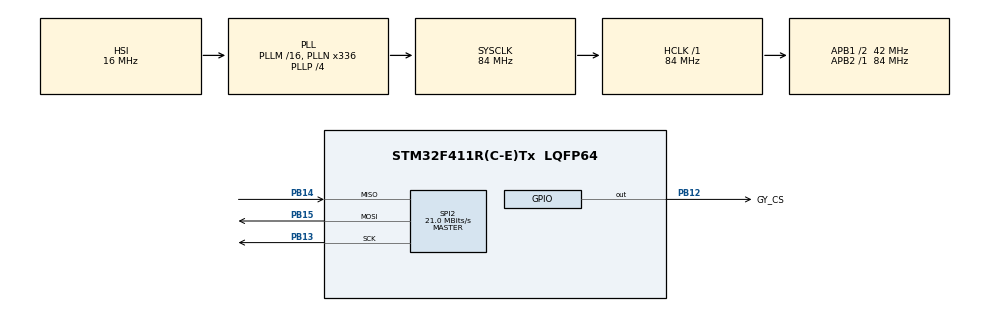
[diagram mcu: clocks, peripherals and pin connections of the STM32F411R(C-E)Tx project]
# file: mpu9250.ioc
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Mcu.Family=STM32F4
Mcu.Name=STM32F411R(C-E)Tx
Mcu.Package=LQFP64
NVIC.PriorityGroup=NVIC_PRIORITYGROUP_0
PA13.Mode=Serial_Wire
PA13.Signal=SYS_JTMS-SWDIO
PA14.Mode=Serial_Wire
PA14.Signal=SYS_JTCK-SWCLK
PB12.GPIO_Label=GY_CS
PB12.Signal=GPIO_Output
PB13.Mode=Full_Duplex_Master
PB13.Signal=SPI2_SCK
PB14.Mode=Full_Duplex_Master
PB14.Signal=SPI2_MISO
PB15.Mode=Full_Duplex_Master
PB15.Signal=SPI2_MOSI
PH0\ -\ OSC_IN.Mode=HSE-External-Oscillator
PH0\ -\ OSC_IN.Signal=RCC_OSC_IN
PH1\ -\ OSC_OUT.Mode=HSE-External-Oscillator
PH1\ -\ OSC_OUT.Signal=RCC_OSC_OUT
ProjectManager.HeapSize=0x200
ProjectManager.StackSize=0x400
ProjectManager.TargetToolchain=MDK-ARM V5
RCC.48MHZClocksFreq_Value=84000000
RCC.AHBFreq_Value=84000000
RCC.APB1CLKDivider=RCC_HCLK_DIV2
RCC.APB1Freq_Value=42000000
RCC.APB1TimFreq_Value=84000000
RCC.APB2Freq_Value=84000000
RCC.APB2TimFreq_Value=84000000
RCC.CortexFreq_Value=84000000
RCC.FLatency-AdvancedSettings=FLASH_LATENCY_2
RCC.HCLKFreq_Value=84000000
RCC.HSE_VALUE=8000000
RCC.HSI_VALUE=16000000
RCC.LSE_VALUE=32768
RCC.PLLN=336
RCC.PLLP=RCC_PLLP_DIV4
RCC.SYSCLKFreq_VALUE=84000000
RCC.SYSCLKSource=RCC_SYSCLKSOURCE_PLLCLK
RCC.VCOOutputFreq_Value=336000000
SPI2.CalculateBaudRate=21.0 MBits/s
SPI2.Direction=SPI_DIRECTION_2LINES
SPI2.Mode=SPI_MODE_MASTER
SPI2.VirtualType=VM_MASTER
board=NUCLEO-F411RE

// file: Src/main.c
/* USER CODE BEGIN Header */
/**
  ******************************************************************************
  * @file           : main.c
  * @brief          : Main program body
  ******************************************************************************
  ** This notice applies to any and all portions of this file
  * that are not between comment pairs USER CODE BEGIN and
  * USER CODE END. Other portions of this file, whether
  * inserted by the user or by software development tools
  * are owned by their respective copyright owners.
  *
  * COPYRIGHT(c) 2019 STMicroelectronics
  *
  * Redistribution and use in source and binary forms, with or without modification,
  * are permitted provided that the following conditions are met:
  *   1. Redistributions of source code must retain the above copyright notice,
  *      this list of conditions and the following disclaimer.
  *   2. Redistributions in binary form must reproduce the above copyright notice,
  *      this list of conditions and the following disclaimer in the documentation
  *      and/or other materials provided with the distribution.
  *   3. Neither the name of STMicroelectronics nor the names of its contributors
  *      may be used to endorse or promote products derived from this software
  *      without specific prior written permission.
  *
  * THIS SOFTWARE IS PROVIDED BY THE COPYRIGHT HOLDERS AND CONTRIBUTORS "AS IS"
  * AND ANY EXPRESS OR IMPLIED WARRANTIES, INCLUDING, BUT NOT LIMITED TO, THE
  * IMPLIED WARRANTIES OF MERCHANTABILITY AND FITNESS FOR A PARTICULAR PURPOSE ARE
  * DISCLAIMED. IN NO EVENT SHALL THE COPYRIGHT HOLDER OR CONTRIBUTORS BE LIABLE
  * FOR ANY DIRECT, INDIRECT, INCIDENTAL, SPECIAL, EXEMPLARY, OR CONSEQUENTIAL
  * DAMAGES (INCLUDING, BUT NOT LIMITED TO, PROCUREMENT OF SUBSTITUTE GOODS OR
  * SERVICES; LOSS OF USE, DATA, OR PROFITS; OR BUSINESS INTERRUPTION) HOWEVER
  * CAUSED AND ON ANY THEORY OF LIABILITY, WHETHER IN CONTRACT, STRICT LIABILITY,
  * OR TORT (INCLUDING NEGLIGENCE OR OTHERWISE) ARISING IN ANY WAY OUT OF THE USE
  * OF THIS SOFTWARE, EVEN IF ADVISED OF THE POSSIBILITY OF SUCH DAMAGE.
  *
  ******************************************************************************
  */
/* USER CODE END Header */

#include "main.h"

/* USER CODE BEGIN Includes */
#include <stdint.h>
#include "MPU9250.h"

/* USER CODE END Includes */

SPI_HandleTypeDef hspi2;

/* USER CODE BEGIN PV */
int16_t AccData[3], GyroData[3], MagData[3];

/* USER CODE END PV */

void SystemClock_Config(void);
static void MX_GPIO_Init(void);
static void MX_SPI2_Init(void);

int main(void)
{

  /* MCU Configuration--------------------------------------------------------*/

  /* Reset of all peripherals, Initializes the Flash interface and the Systick. */
  HAL_Init();

  /* Configure the system clock */
  SystemClock_Config();

  /* Initialize all configured peripherals */
  MX_GPIO_Init();
  MX_SPI2_Init();
  /* USER CODE BEGIN 2 */
		MPU9250_Init();

  /* USER CODE END 2 */

  /* Infinite loop */
  while (1)
  {

    /* USER CODE BEGIN 3 */
	MPU9250_GetData(AccData, GyroData, MagData);
  }
  /* USER CODE END 3 */
}

void SystemClock_Config(void)
{
  RCC_OscInitTypeDef RCC_OscInitStruct = {0};
  RCC_ClkInitTypeDef RCC_ClkInitStruct = {0};

  /**Configure the main internal regulator output voltage
  */
  __HAL_RCC_PWR_CLK_ENABLE();
  __HAL_PWR_VOLTAGESCALING_CONFIG(PWR_REGULATOR_VOLTAGE_SCALE1);
  /**Initializes the CPU, AHB and APB busses clocks
  */
  RCC_OscInitStruct.OscillatorType = RCC_OSCILLATORTYPE_HSI;
  RCC_OscInitStruct.HSIState = RCC_HSI_ON;
  RCC_OscInitStruct.HSICalibrationValue = RCC_HSICALIBRATION_DEFAULT;
  RCC_OscInitStruct.PLL.PLLState = RCC_PLL_ON;
  RCC_OscInitStruct.PLL.PLLSource = RCC_PLLSOURCE_HSI;
  RCC_OscInitStruct.PLL.PLLM = 16;
  RCC_OscInitStruct.PLL.PLLN = 336;
  RCC_OscInitStruct.PLL.PLLP = RCC_PLLP_DIV4;
  RCC_OscInitStruct.PLL.PLLQ = 4;
  if (HAL_RCC_OscConfig(&RCC_OscInitStruct) != HAL_OK)
  {
    Error_Handler();
  }
  /**Initializes the CPU, AHB and APB busses clocks
  */
  RCC_ClkInitStruct.ClockType = RCC_CLOCKTYPE_HCLK|RCC_CLOCKTYPE_SYSCLK
                              |RCC_CLOCKTYPE_PCLK1|RCC_CLOCKTYPE_PCLK2;
  RCC_ClkInitStruct.SYSCLKSource = RCC_SYSCLKSOURCE_PLLCLK;
  RCC_ClkInitStruct.AHBCLKDivider = RCC_SYSCLK_DIV1;
  RCC_ClkInitStruct.APB1CLKDivider = RCC_HCLK_DIV2;
  RCC_ClkInitStruct.APB2CLKDivider = RCC_HCLK_DIV1;

  if (HAL_RCC_ClockConfig(&RCC_ClkInitStruct, FLASH_LATENCY_2) != HAL_OK)
  {
    Error_Handler();
  }
}

static void MX_SPI2_Init(void)
{

  /* SPI2 parameter configuration*/
  hspi2.Instance = SPI2;
  hspi2.Init.Mode = SPI_MODE_MASTER;
  hspi2.Init.Direction = SPI_DIRECTION_2LINES;
  hspi2.Init.DataSize = SPI_DATASIZE_8BIT;
  hspi2.Init.CLKPolarity = SPI_POLARITY_LOW;
  hspi2.Init.CLKPhase = SPI_PHASE_1EDGE;
  hspi2.Init.NSS = SPI_NSS_SOFT;
  hspi2.Init.BaudRatePrescaler = SPI_BAUDRATEPRESCALER_2;
  hspi2.Init.FirstBit = SPI_FIRSTBIT_MSB;
  hspi2.Init.TIMode = SPI_TIMODE_DISABLE;
  hspi2.Init.CRCCalculation = SPI_CRCCALCULATION_DISABLE;
  hspi2.Init.CRCPolynomial = 10;
  if (HAL_SPI_Init(&hspi2) != HAL_OK)
  {
    Error_Handler();
  }

}

static void MX_GPIO_Init(void)
{
  GPIO_InitTypeDef GPIO_InitStruct = {0};

  /* GPIO Ports Clock Enable */
  __HAL_RCC_GPIOH_CLK_ENABLE();
  __HAL_RCC_GPIOB_CLK_ENABLE();
  __HAL_RCC_GPIOA_CLK_ENABLE();

  /*Configure GPIO pin Output Level */
  HAL_GPIO_WritePin(GY_CS_GPIO_Port, GY_CS_Pin, GPIO_PIN_RESET);

  /*Configure GPIO pin : GY_CS_Pin */
  GPIO_InitStruct.Pin = GY_CS_Pin;
  GPIO_InitStruct.Mode = GPIO_MODE_OUTPUT_PP;
  GPIO_InitStruct.Pull = GPIO_NOPULL;
  GPIO_InitStruct.Speed = GPIO_SPEED_FREQ_LOW;
  HAL_GPIO_Init(GY_CS_GPIO_Port, &GPIO_InitStruct);

}

void Error_Handler(void)
{
}

/************************ (C) COPYRIGHT STMicroelectronics *****END OF FILE****/
